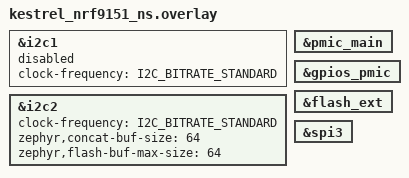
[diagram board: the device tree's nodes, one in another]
&i2c1 {
	status = "disabled";
	clock-frequency = <I2C_BITRATE_STANDARD>;
};

&i2c2 {
	status = "okay";
	clock-frequency = <I2C_BITRATE_STANDARD>;
    zephyr,concat-buf-size = <64>;
    zephyr,flash-buf-max-size = <64>;
};






&pmic_main {
	status = "okay";
};

&gpios_pmic {
	status = "okay";
};

&flash_ext {
    status = "okay";
};

&spi3 {
	status = "okay";
};

